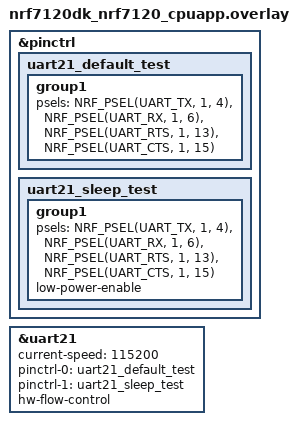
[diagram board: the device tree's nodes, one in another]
/* Required loopbacks:
 * P1.04 <-> P1.06
 * P1.13 <-> P1.15
 */

&pinctrl {
	uart21_default_test: uart21_default_test {
		group1 {
			psels = <NRF_PSEL(UART_TX, 1, 4)>,
				<NRF_PSEL(UART_RX, 1, 6)>,
				<NRF_PSEL(UART_RTS, 1, 13)>,
				<NRF_PSEL(UART_CTS, 1, 15)>;
		};
	};

	uart21_sleep_test: uart21_sleep_test {
		group1 {
			psels = <NRF_PSEL(UART_TX, 1, 4)>,
				<NRF_PSEL(UART_RX, 1, 6)>,
				<NRF_PSEL(UART_RTS, 1, 13)>,
				<NRF_PSEL(UART_CTS, 1, 15)>;
			low-power-enable;
		};
	};
};

dut: &uart21 {
	status = "okay";
	current-speed = <115200>;
	pinctrl-0 = <&uart21_default_test>;
	pinctrl-1 = <&uart21_sleep_test>;
	pinctrl-names = "default", "sleep";
	hw-flow-control;
};
